# CY8C5267AXI_LP051 register map
File version: 0.1
CY8C52LP
Registers are 8-bit, read-write, no defined reset value unless marked. A register's access mark holds for its fields unless they carry their own. Offsets are from the block's base; lines under a group give offsets from that group; [hi:lo] are bit positions; {n}, {i} and the like mark numbered series; 'fields as' and 'values as' point back to an identical list; <NAME> marks a mode.

## Memory map
0x00000000 DataOut_Port1
0x00000000 DataIn_Port5
0x00000000 DataOut_Port4
0x00000000 DataIn_Port1
0x00000000 DataOut_Port12
0x00000000 DataIn_Port6
0x00000000 DataOut_Port5
0x00000000 DataOut_Port6
0x00000000 DataIn_Port12
0x00000000 DataIn_Port2
0x00000000 I2C_EEPROM
0x00000000 USBUART — USBFS
0x00000000 DataIn_Port3
0x00000000 DataIn_Port0
0x00000000 DataOut_Port0
0x00000000 Dir_Ctl
0x00000000 DataIn_Port4
0x00000000 DataOut_Port3
0x00000000 DataOut_Port2

## DataOut_Port1
Base 0x00000000
0x4000657B DataOut_Port1_CONTROL_REG

## DataIn_Port5
Base 0x00000000
0x4000656B DataIn_Port5_STATUS_REG
0x4000658B DataIn_Port5_MASK_REG
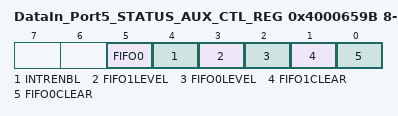
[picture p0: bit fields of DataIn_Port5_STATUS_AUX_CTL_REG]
0x4000659B DataIn_Port5_STATUS_AUX_CTL_REG
  [5] FIFO0 — FIFO0 clear
    1=ENABLED (Enable counter); 0=DISABLED (Disable counter)
  [4] INTRENBL — Enables or disables the Interrupt
    1=ENABLED (Interrupt enabled); 0=DISABLED (Interrupt disabled)
  [3] FIFO1LEVEL — FIFO level
    1=ENABLED (FIFO LVL: input mode: FIFO at least 1/2 empty; output mode: FIFO at least 1/2 full); 0=DISABLED (FIFO LVL: input mode: FIFO not full; output mode: FIFO not empty)
  [2] FIFO0LEVEL — FIFO level
    values as FIFO1LEVEL
  [1] FIFO1CLEAR — FIFO clear
    1=ENABLED (Clear FIFO state); 0=DISABLED (Normal FIFO operation)
  [0] FIFO0CLEAR — FIFO clear
    values as FIFO1CLEAR

## DataOut_Port4
Base 0x00000000
0x40006473 DataOut_Port4_CONTROL_REG

## DataIn_Port1
Base 0x00000000
0x4000656A DataIn_Port1_STATUS_REG
0x4000658A DataIn_Port1_MASK_REG
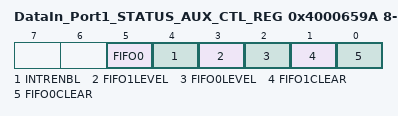
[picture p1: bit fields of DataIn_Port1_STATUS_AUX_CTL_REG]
0x4000659A DataIn_Port1_STATUS_AUX_CTL_REG
  [5] FIFO0 — FIFO0 clear
    1=ENABLED (Enable counter); 0=DISABLED (Disable counter)
  [4] INTRENBL — Enables or disables the Interrupt
    1=ENABLED (Interrupt enabled); 0=DISABLED (Interrupt disabled)
  [3] FIFO1LEVEL — FIFO level
    1=ENABLED (FIFO LVL: input mode: FIFO at least 1/2 empty; output mode: FIFO at least 1/2 full); 0=DISABLED (FIFO LVL: input mode: FIFO not full; output mode: FIFO not empty)
  [2] FIFO0LEVEL — FIFO level
    values as FIFO1LEVEL
  [1] FIFO1CLEAR — FIFO clear
    1=ENABLED (Clear FIFO state); 0=DISABLED (Normal FIFO operation)
  [0] FIFO0CLEAR — FIFO clear
    values as FIFO1CLEAR

## DataOut_Port12
Base 0x00000000
0x40006574 DataOut_Port12_CONTROL_REG

## DataIn_Port6
Base 0x00000000
0x4000646A DataIn_Port6_STATUS_REG
0x4000648A DataIn_Port6_MASK_REG
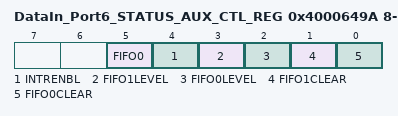
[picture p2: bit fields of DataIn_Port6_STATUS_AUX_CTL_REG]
0x4000649A DataIn_Port6_STATUS_AUX_CTL_REG
  [5] FIFO0 — FIFO0 clear
    1=ENABLED (Enable counter); 0=DISABLED (Disable counter)
  [4] INTRENBL — Enables or disables the Interrupt
    1=ENABLED (Interrupt enabled); 0=DISABLED (Interrupt disabled)
  [3] FIFO1LEVEL — FIFO level
    1=ENABLED (FIFO LVL: input mode: FIFO at least 1/2 empty; output mode: FIFO at least 1/2 full); 0=DISABLED (FIFO LVL: input mode: FIFO not full; output mode: FIFO not empty)
  [2] FIFO0LEVEL — FIFO level
    values as FIFO1LEVEL
  [1] FIFO1CLEAR — FIFO clear
    1=ENABLED (Clear FIFO state); 0=DISABLED (Normal FIFO operation)
  [0] FIFO0CLEAR — FIFO clear
    values as FIFO1CLEAR

## DataOut_Port5
Base 0x00000000
0x4000657A DataOut_Port5_CONTROL_REG

## DataOut_Port6
Base 0x00000000
0x4000647C DataOut_Port6_CONTROL_REG

## DataIn_Port12
Base 0x00000000
0x40006564 DataIn_Port12_STATUS_REG
0x40006584 DataIn_Port12_MASK_REG
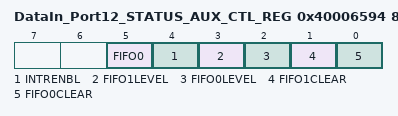
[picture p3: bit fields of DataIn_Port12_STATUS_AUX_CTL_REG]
0x40006594 DataIn_Port12_STATUS_AUX_CTL_REG
  [5] FIFO0 — FIFO0 clear
    1=ENABLED (Enable counter); 0=DISABLED (Disable counter)
  [4] INTRENBL — Enables or disables the Interrupt
    1=ENABLED (Interrupt enabled); 0=DISABLED (Interrupt disabled)
  [3] FIFO1LEVEL — FIFO level
    1=ENABLED (FIFO LVL: input mode: FIFO at least 1/2 empty; output mode: FIFO at least 1/2 full); 0=DISABLED (FIFO LVL: input mode: FIFO not full; output mode: FIFO not empty)
  [2] FIFO0LEVEL — FIFO level
    values as FIFO1LEVEL
  [1] FIFO1CLEAR — FIFO clear
    1=ENABLED (Clear FIFO state); 0=DISABLED (Normal FIFO operation)
  [0] FIFO0CLEAR — FIFO clear
    values as FIFO1CLEAR
